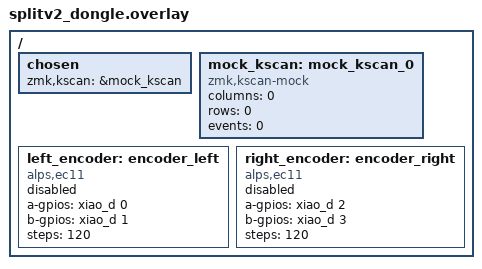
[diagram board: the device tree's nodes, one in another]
/*
 * Copyright (c) 2026 The ZMK Contributors
 * SPDX-License-Identifier: MIT
 *
 * Seeed Studio XIAO BLE (nRF52840) USB central. It has no keys and no
 * Pro Micro socket, so this overlay never references &pro_micro.
 * Key events arrive over BLE from the two nice!nano halves.
 *
 * The keymap still lists two encoders. These nodes stay disabled so the
 * dongle does not scan its own pins. The halves own the real EC11 drivers.
 * D0 through D3 are unused placeholders required by the EC11 binding.
 */

#include "splitv2.dtsi"

/ {
    chosen {
        zmk,kscan = &mock_kscan;
    };

    mock_kscan: mock_kscan_0 {
        compatible = "zmk,kscan-mock";
        columns = <0>;
        rows = <0>;
        events = <0>;
    };

    left_encoder: encoder_left {
        compatible = "alps,ec11";
        a-gpios = <&xiao_d 0 (GPIO_ACTIVE_HIGH | GPIO_PULL_UP)>;
        b-gpios = <&xiao_d 1 (GPIO_ACTIVE_HIGH | GPIO_PULL_UP)>;
        steps = <120>;
        status = "disabled";
    };

    right_encoder: encoder_right {
        compatible = "alps,ec11";
        a-gpios = <&xiao_d 2 (GPIO_ACTIVE_HIGH | GPIO_PULL_UP)>;
        b-gpios = <&xiao_d 3 (GPIO_ACTIVE_HIGH | GPIO_PULL_UP)>;
        steps = <120>;
        status = "disabled";
    };
};
